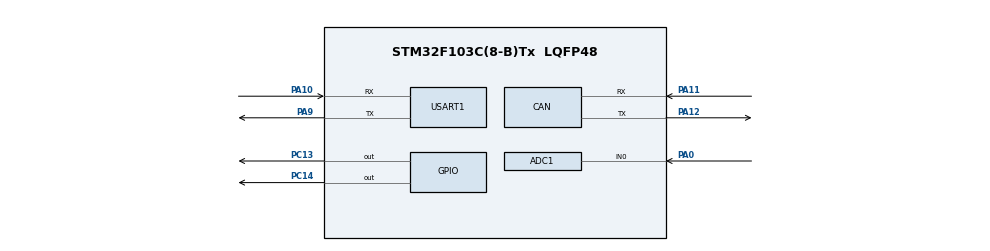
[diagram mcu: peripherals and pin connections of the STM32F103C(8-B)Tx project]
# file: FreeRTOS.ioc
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ADC1.Channel-0\#ChannelRegularConversion=ADC_CHANNEL_0
ADC1.NbrOfConversionFlag=1
ADC1.Rank-0\#ChannelRegularConversion=1
ADC1.SamplingTime-0\#ChannelRegularConversion=ADC_SAMPLETIME_1CYCLE_5
ADC1.master=1
CAN.BS1=CAN_BS1_4TQ
CAN.BS2=CAN_BS2_2TQ
CAN.CalculateTimeBit=14000
CAN.CalculateTimeQuantum=2000.0
FREERTOS.Mutexes01=uartMUTEX,Dynamic,NULL
FREERTOS.Tasks01=defaultTask,24,128,Thread1,Default,NULL,Dynamic,NULL,NULL;myTask02,8,128,Thread2,Default,NULL,Dynamic,NULL,NULL
Mcu.Family=STM32F1
Mcu.Name=STM32F103C(8-B)Tx
Mcu.Package=LQFP48
NVIC.CAN1_RX1_IRQn=true\:0\:0\:false\:false\:true\:false\:true\:true
NVIC.PriorityGroup=NVIC_PRIORITYGROUP_4
NVIC.TIM2_IRQn=true\:0\:0\:false\:false\:true\:false\:false\:true
NVIC.TimeBase=TIM2_IRQn
NVIC.TimeBaseIP=TIM2
PA0-WKUP.Signal=ADCx_IN0
PA10.Mode=Asynchronous
PA10.Signal=USART1_RX
PA11.Mode=Master
PA11.Signal=CAN_RX
PA12.Mode=Master
PA12.Signal=CAN_TX
PA13.Mode=Serial_Wire
PA13.Signal=SYS_JTMS-SWDIO
PA14.Mode=Serial_Wire
PA14.Signal=SYS_JTCK-SWCLK
PA9.Mode=Asynchronous
PA9.Signal=USART1_TX
PC13-TAMPER-RTC.Signal=GPIO_Output
PC14-OSC32_IN.Signal=GPIO_Output
PD0-OSC_IN.Mode=HSE-External-Oscillator
PD0-OSC_IN.Signal=RCC_OSC_IN
PD1-OSC_OUT.Mode=HSE-External-Oscillator
PD1-OSC_OUT.Signal=RCC_OSC_OUT
ProjectManager.HeapSize=0x200
ProjectManager.StackSize=0x400
ProjectManager.TargetToolchain=MDK-ARM V5.27
RCC.APB1Freq_Value=8000000
RCC.APB2Freq_Value=8000000
RCC.PLLSourceVirtual=RCC_PLLSOURCE_HSE
RCC.USBFreq_Value=16000000
SH.ADCx_IN0.0=ADC1_IN0,IN0
USART1.VirtualMode=VM_ASYNC
VP_FREERTOS_VS_CMSIS_V2.Mode=CMSIS_V2
VP_SYS_VS_tim2.Mode=TIM2
VP_TIM3_VS_ClockSourceINT.Mode=Internal
VP_TIM4_VS_ClockSourceINT.Mode=Internal
board=custom

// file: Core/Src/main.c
/* USER CODE BEGIN Header */
/**
  ******************************************************************************
  * @file           : main.c
  * @brief          : Main program body
  ******************************************************************************
  * @attention
  *
  * <h2><center>&copy; Copyright (c) 2020 STMicroelectronics.
  * All rights reserved.</center></h2>
  *
  * This software component is licensed by ST under Ultimate Liberty license
  * SLA0044, the "License"; You may not use this file except in compliance with
  * the License. You may obtain a copy of the License at:
  *                             www.st.com/SLA0044
  *
  ******************************************************************************
  */
/* USER CODE END Header */
#include "main.h"
#include "cmsis_os.h"

ADC_HandleTypeDef hadc1;

CAN_HandleTypeDef hcan;

TIM_HandleTypeDef htim3;
TIM_HandleTypeDef htim4;

UART_HandleTypeDef huart1;

/* Definitions for defaultTask */
osThreadId_t defaultTaskHandle;
const osThreadAttr_t defaultTask_attributes = {
  .name = "defaultTask",
  .priority = (osPriority_t) osPriorityNormal,
  .stack_size = 128 * 4
};
/* Definitions for myTask02 */
osThreadId_t myTask02Handle;
const osThreadAttr_t myTask02_attributes = {
  .name = "myTask02",
  .priority = (osPriority_t) osPriorityLow,
  .stack_size = 128 * 4
};
/* Definitions for uartMUTEX */
osMutexId_t uartMUTEXHandle;
const osMutexAttr_t uartMUTEX_attributes = {
  .name = "uartMUTEX"
};

void SystemClock_Config(void);
static void MX_GPIO_Init(void);
static void MX_ADC1_Init(void);
static void MX_CAN_Init(void);
static void MX_TIM3_Init(void);
static void MX_TIM4_Init(void);
static void MX_USART1_UART_Init(void);
void Thread1(void *argument);
void Thread2(void *argument);

int main(void)
{

  /* MCU Configuration--------------------------------------------------------*/

  /* Reset of all peripherals, Initializes the Flash interface and the Systick. */
  HAL_Init();

  /* Configure the system clock */
  SystemClock_Config();

  /* Initialize all configured peripherals */
  MX_GPIO_Init();
  MX_ADC1_Init();
  MX_CAN_Init();
  MX_TIM3_Init();
  MX_TIM4_Init();
  MX_USART1_UART_Init();

  /* Init scheduler */
  osKernelInitialize();
  /* Create the mutex(es) */
  /* creation of uartMUTEX */
  uartMUTEXHandle = osMutexNew(&uartMUTEX_attributes);

  /* Create the thread(s) */
  /* creation of defaultTask */
  defaultTaskHandle = osThreadNew(Thread1, NULL, &defaultTask_attributes);

  /* creation of myTask02 */
  myTask02Handle = osThreadNew(Thread2, NULL, &myTask02_attributes);

  /* Start scheduler */
  osKernelStart();

  /* We should never get here as control is now taken by the scheduler */
  /* Infinite loop */
  while (1)
  {

  }
}

void SystemClock_Config(void)
{
  RCC_OscInitTypeDef RCC_OscInitStruct = {0};
  RCC_ClkInitTypeDef RCC_ClkInitStruct = {0};
  RCC_PeriphCLKInitTypeDef PeriphClkInit = {0};

  /** Initializes the RCC Oscillators according to the specified parameters
  * in the RCC_OscInitTypeDef structure.
  */
  RCC_OscInitStruct.OscillatorType = RCC_OSCILLATORTYPE_HSI;
  RCC_OscInitStruct.HSIState = RCC_HSI_ON;
  RCC_OscInitStruct.HSICalibrationValue = RCC_HSICALIBRATION_DEFAULT;
  RCC_OscInitStruct.PLL.PLLState = RCC_PLL_NONE;
  if (HAL_RCC_OscConfig(&RCC_OscInitStruct) != HAL_OK)
  {
    Error_Handler();
  }
  /** Initializes the CPU, AHB and APB buses clocks
  */
  RCC_ClkInitStruct.ClockType = RCC_CLOCKTYPE_HCLK|RCC_CLOCKTYPE_SYSCLK
                              |RCC_CLOCKTYPE_PCLK1|RCC_CLOCKTYPE_PCLK2;
  RCC_ClkInitStruct.SYSCLKSource = RCC_SYSCLKSOURCE_HSI;
  RCC_ClkInitStruct.AHBCLKDivider = RCC_SYSCLK_DIV1;
  RCC_ClkInitStruct.APB1CLKDivider = RCC_HCLK_DIV1;
  RCC_ClkInitStruct.APB2CLKDivider = RCC_HCLK_DIV1;

  if (HAL_RCC_ClockConfig(&RCC_ClkInitStruct, FLASH_LATENCY_0) != HAL_OK)
  {
    Error_Handler();
  }
  PeriphClkInit.PeriphClockSelection = RCC_PERIPHCLK_ADC;
  PeriphClkInit.AdcClockSelection = RCC_ADCPCLK2_DIV2;
  if (HAL_RCCEx_PeriphCLKConfig(&PeriphClkInit) != HAL_OK)
  {
    Error_Handler();
  }
}

static void MX_ADC1_Init(void)
{

  ADC_ChannelConfTypeDef sConfig = {0};

  /** Common config
  */
  hadc1.Instance = ADC1;
  hadc1.Init.ScanConvMode = ADC_SCAN_DISABLE;
  hadc1.Init.ContinuousConvMode = DISABLE;
  hadc1.Init.DiscontinuousConvMode = DISABLE;
  hadc1.Init.ExternalTrigConv = ADC_SOFTWARE_START;
  hadc1.Init.DataAlign = ADC_DATAALIGN_RIGHT;
  hadc1.Init.NbrOfConversion = 1;
  if (HAL_ADC_Init(&hadc1) != HAL_OK)
  {
    Error_Handler();
  }
  /** Configure Regular Channel
  */
  sConfig.Channel = ADC_CHANNEL_0;
  sConfig.Rank = ADC_REGULAR_RANK_1;
  sConfig.SamplingTime = ADC_SAMPLETIME_1CYCLE_5;
  if (HAL_ADC_ConfigChannel(&hadc1, &sConfig) != HAL_OK)
  {
    Error_Handler();
  }

}

static void MX_CAN_Init(void)
{

  hcan.Instance = CAN1;
  hcan.Init.Prescaler = 16;
  hcan.Init.Mode = CAN_MODE_NORMAL;
  hcan.Init.SyncJumpWidth = CAN_SJW_1TQ;
  hcan.Init.TimeSeg1 = CAN_BS1_4TQ;
  hcan.Init.TimeSeg2 = CAN_BS2_2TQ;
  hcan.Init.TimeTriggeredMode = DISABLE;
  hcan.Init.AutoBusOff = DISABLE;
  hcan.Init.AutoWakeUp = DISABLE;
  hcan.Init.AutoRetransmission = DISABLE;
  hcan.Init.ReceiveFifoLocked = DISABLE;
  hcan.Init.TransmitFifoPriority = DISABLE;
  if (HAL_CAN_Init(&hcan) != HAL_OK)
  {
    Error_Handler();
  }

}

static void MX_TIM3_Init(void)
{

  TIM_ClockConfigTypeDef sClockSourceConfig = {0};
  TIM_MasterConfigTypeDef sMasterConfig = {0};

  htim3.Instance = TIM3;
  htim3.Init.Prescaler = 0;
  htim3.Init.CounterMode = TIM_COUNTERMODE_UP;
  htim3.Init.Period = 65535;
  htim3.Init.ClockDivision = TIM_CLOCKDIVISION_DIV1;
  htim3.Init.AutoReloadPreload = TIM_AUTORELOAD_PRELOAD_DISABLE;
  if (HAL_TIM_Base_Init(&htim3) != HAL_OK)
  {
    Error_Handler();
  }
  sClockSourceConfig.ClockSource = TIM_CLOCKSOURCE_INTERNAL;
  if (HAL_TIM_ConfigClockSource(&htim3, &sClockSourceConfig) != HAL_OK)
  {
    Error_Handler();
  }
  sMasterConfig.MasterOutputTrigger = TIM_TRGO_RESET;
  sMasterConfig.MasterSlaveMode = TIM_MASTERSLAVEMODE_DISABLE;
  if (HAL_TIMEx_MasterConfigSynchronization(&htim3, &sMasterConfig) != HAL_OK)
  {
    Error_Handler();
  }

}

static void MX_TIM4_Init(void)
{

  TIM_ClockConfigTypeDef sClockSourceConfig = {0};
  TIM_MasterConfigTypeDef sMasterConfig = {0};

  htim4.Instance = TIM4;
  htim4.Init.Prescaler = 0;
  htim4.Init.CounterMode = TIM_COUNTERMODE_UP;
  htim4.Init.Period = 65535;
  htim4.Init.ClockDivision = TIM_CLOCKDIVISION_DIV1;
  htim4.Init.AutoReloadPreload = TIM_AUTORELOAD_PRELOAD_DISABLE;
  if (HAL_TIM_Base_Init(&htim4) != HAL_OK)
  {
    Error_Handler();
  }
  sClockSourceConfig.ClockSource = TIM_CLOCKSOURCE_INTERNAL;
  if (HAL_TIM_ConfigClockSource(&htim4, &sClockSourceConfig) != HAL_OK)
  {
    Error_Handler();
  }
  sMasterConfig.MasterOutputTrigger = TIM_TRGO_RESET;
  sMasterConfig.MasterSlaveMode = TIM_MASTERSLAVEMODE_DISABLE;
  if (HAL_TIMEx_MasterConfigSynchronization(&htim4, &sMasterConfig) != HAL_OK)
  {
    Error_Handler();
  }

}

static void MX_USART1_UART_Init(void)
{

  huart1.Instance = USART1;
  huart1.Init.BaudRate = 115200;
  huart1.Init.WordLength = UART_WORDLENGTH_8B;
  huart1.Init.StopBits = UART_STOPBITS_1;
  huart1.Init.Parity = UART_PARITY_NONE;
  huart1.Init.Mode = UART_MODE_TX_RX;
  huart1.Init.HwFlowCtl = UART_HWCONTROL_NONE;
  huart1.Init.OverSampling = UART_OVERSAMPLING_16;
  if (HAL_UART_Init(&huart1) != HAL_OK)
  {
    Error_Handler();
  }

}

static void MX_GPIO_Init(void)
{
  GPIO_InitTypeDef GPIO_InitStruct = {0};

  /* GPIO Ports Clock Enable */
  __HAL_RCC_GPIOC_CLK_ENABLE();
  __HAL_RCC_GPIOD_CLK_ENABLE();
  __HAL_RCC_GPIOA_CLK_ENABLE();

  /*Configure GPIO pin Output Level */
  HAL_GPIO_WritePin(GPIOC, GPIO_PIN_13|GPIO_PIN_14, GPIO_PIN_RESET);

  /*Configure GPIO pins : PC13 PC14 */
  GPIO_InitStruct.Pin = GPIO_PIN_13|GPIO_PIN_14;
  GPIO_InitStruct.Mode = GPIO_MODE_OUTPUT_PP;
  GPIO_InitStruct.Pull = GPIO_NOPULL;
  GPIO_InitStruct.Speed = GPIO_SPEED_FREQ_LOW;
  HAL_GPIO_Init(GPIOC, &GPIO_InitStruct);

}

void Thread1(void *argument)
{
  /* USER CODE BEGIN 5 */

	uint8_t txData[20] = "Hello from thread1\r\n";
  /* Infinite loop */
  for(;;)
  {

		HAL_UART_Transmit(&huart1, txData, 20, 1);
		HAL_GPIO_WritePin(GPIOC, GPIO_PIN_13, GPIO_PIN_SET );
		osDelay(40);
		 HAL_GPIO_WritePin(GPIOC, GPIO_PIN_13, GPIO_PIN_RESET );
    osDelay(60);
  }
  /* USER CODE END 5 */
}

void Thread2(void *argument)
{
  /* USER CODE BEGIN Thread2 */
  /* Infinite loop */
  for(;;)
  {
		HAL_GPIO_TogglePin(GPIOC, GPIO_PIN_14);

    osDelay(1000);
  }
  /* USER CODE END Thread2 */
}

void HAL_TIM_PeriodElapsedCallback(TIM_HandleTypeDef *htim)
{
  if (htim->Instance == TIM2) {
    HAL_IncTick();
  }
}

void Error_Handler(void)
{
}

/************************ (C) COPYRIGHT STMicroelectronics *****END OF FILE****/
